# ECC_AGGR_ECC_AGGR_3F00F000h register map
Vendor: Texas Instruments
Peripheral module from a debugger description file (folder AM275x).
Registers are 32-bit, access not given, reset 0x0 unless marked. A register's access mark holds for its fields unless they carry their own. Offsets are as the file gives them; lines under a group give offsets from that group; [hi:lo] are bit positions; {n}, {i} and the like mark numbered series; 'fields as' and 'values as' point back to an identical list; <NAME> marks a mode.

## ecc_aggr
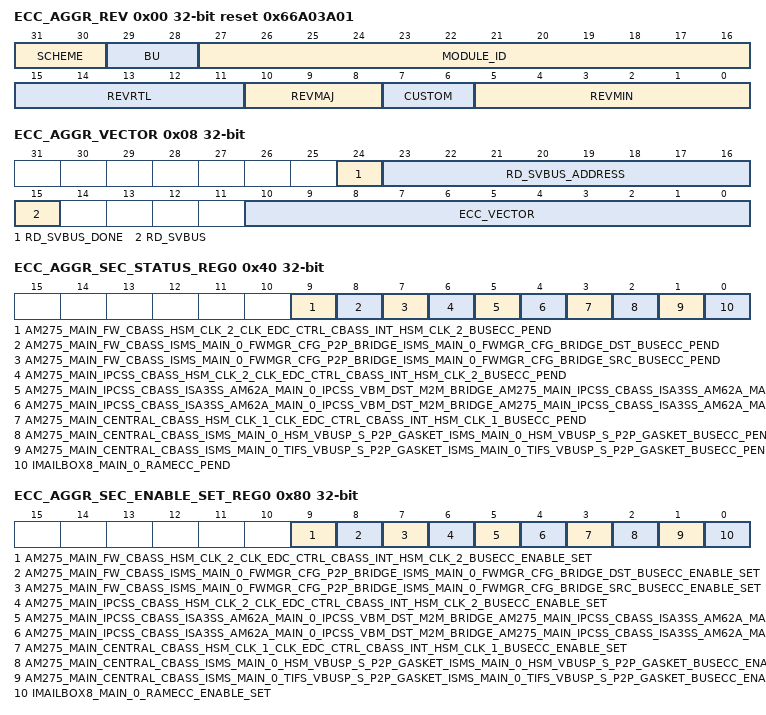
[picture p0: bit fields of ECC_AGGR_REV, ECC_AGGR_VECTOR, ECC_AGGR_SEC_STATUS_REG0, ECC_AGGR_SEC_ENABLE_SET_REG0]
0x00 ECC_AGGR_REV ro reset 0x66A03A01 — Revision parameters
  [31:30] SCHEME
  [29:28] BU — Business Unit
  [27:16] MODULE_ID
  [15:11] REVRTL — RTL version
  [10:8] REVMAJ — Major version
  [7:6] CUSTOM — Custom version
  [5:0] REVMIN — Minor version
0x08 ECC_AGGR_VECTOR — ECC Vector Register
  [24] RD_SVBUS_DONE — Status to indicate if read on serial VBUS is complete, write of any value will clear this bit. (access R/W1TC)
  [23:16] RD_SVBUS_ADDRESS rw — Read address
  [15] RD_SVBUS — Write 1 to trigger a read on the serial VBUS (access R/W1TS)
  [10:0] ECC_VECTOR rw — Value written to select the corresponding ECC RAM for control or status
0x0C ECC_AGGR_STAT ro reset 0xA — Misc Status
  [10:0] NUM_RAMS — Indicates the number of RAMS serviced by the ECC aggregator
0x10 ECC_AGGR_RESERVED_SVBUS_j rw — Reference other documents that contain the ECC RAM wrapper and EDC controller serial vbus register sets.
  [31:0] DATA — Serial VBUS register data
0x3C ECC_AGGR_SEC_EOI_REG — EOI Register
  [0] EOI_WR — EOI Register (access R/W1TS)
0x40 ECC_AGGR_SEC_STATUS_REG0 — Interrupt Status Register 0
  [9] AM275_MAIN_FW_CBASS_HSM_CLK_2_CLK_EDC_CTRL_CBASS_INT_HSM_CLK_2_BUSECC_PEND — Interrupt Pending Status for am275_main_fw_cbass_HSM_CLK_2_clk_edc_ctrl_cbass_int_HSM_CLK_2_busecc_pend (access R/W1TS)
  [8] AM275_MAIN_FW_CBASS_ISMS_MAIN_0_FWMGR_CFG_P2P_BRIDGE_ISMS_MAIN_0_FWMGR_CFG_BRIDGE_DST_BUSECC_PEND — Interrupt Pending Status for am275_main_fw_cbass_Isms_main_0_fwmgr_cfg_p2p_bridge_Isms_main_0_fwmgr_cfg_bridge_dst_busecc_pend (access R/W1TS)
  [7] AM275_MAIN_FW_CBASS_ISMS_MAIN_0_FWMGR_CFG_P2P_BRIDGE_ISMS_MAIN_0_FWMGR_CFG_BRIDGE_SRC_BUSECC_PEND — Interrupt Pending Status for am275_main_fw_cbass_Isms_main_0_fwmgr_cfg_p2p_bridge_Isms_main_0_fwmgr_cfg_bridge_src_busecc_pend (access R/W1TS)
  [6] AM275_MAIN_IPCSS_CBASS_HSM_CLK_2_CLK_EDC_CTRL_CBASS_INT_HSM_CLK_2_BUSECC_PEND — Interrupt Pending Status for am275_main_IPCSS_cbass_HSM_CLK_2_clk_edc_ctrl_cbass_int_HSM_CLK_2_busecc_pend (access R/W1TS)
  [5] AM275_MAIN_IPCSS_CBASS_ISA3SS_AM62A_MAIN_0_IPCSS_VBM_DST_M2M_BRIDGE_AM275_MAIN_IPCSS_CBASS_ISA3SS_AM62A_MAIN_0_IPCSS_VBM_DST_M2M_BRIDGE_DST_EDC_CTRL_BUSECC_PEND — Interrupt Pending Status for am275_main_IPCSS_cbass_Isa3ss_am62a_main_0_ipcss_vbm_dst_m2m_bridge_am275_main_IPCSS_cbass_Isa3ss_am62a_main_0_ipcss_vbm_dst_m2m_bridge_dst_edc_ctrl_busecc_pend (access R/W1TS)
  [4] AM275_MAIN_IPCSS_CBASS_ISA3SS_AM62A_MAIN_0_IPCSS_VBM_DST_M2M_BRIDGE_AM275_MAIN_IPCSS_CBASS_ISA3SS_AM62A_MAIN_0_IPCSS_VBM_DST_M2M_BRIDGE_SRC_EDC_CTRL_BUSECC_PEND — Interrupt Pending Status for am275_main_IPCSS_cbass_Isa3ss_am62a_main_0_ipcss_vbm_dst_m2m_bridge_am275_main_IPCSS_cbass_Isa3ss_am62a_main_0_ipcss_vbm_dst_m2m_bridge_src_edc_ctrl_busecc_pend (access R/W1TS)
  [3] AM275_MAIN_CENTRAL_CBASS_HSM_CLK_1_CLK_EDC_CTRL_CBASS_INT_HSM_CLK_1_BUSECC_PEND — Interrupt Pending Status for am275_main_central_cbass_HSM_CLK_1_clk_edc_ctrl_cbass_int_HSM_CLK_1_busecc_pend (access R/W1TS)
  [2] AM275_MAIN_CENTRAL_CBASS_ISMS_MAIN_0_HSM_VBUSP_S_P2P_GASKET_ISMS_MAIN_0_HSM_VBUSP_S_P2P_GASKET_BUSECC_PEND — Interrupt Pending Status for am275_main_central_cbass_Isms_main_0_hsm_vbusp_s_p2p_gasket_Isms_main_0_hsm_vbusp_s_p2p_gasket_busecc_pend (access R/W1TS)
  [1] AM275_MAIN_CENTRAL_CBASS_ISMS_MAIN_0_TIFS_VBUSP_S_P2P_GASKET_ISMS_MAIN_0_TIFS_VBUSP_S_P2P_GASKET_BUSECC_PEND — Interrupt Pending Status for am275_main_central_cbass_Isms_main_0_tifs_vbusp_s_p2p_gasket_Isms_main_0_tifs_vbusp_s_p2p_gasket_busecc_pend (access R/W1TS)
  [0] IMAILBOX8_MAIN_0_RAMECC_PEND — Interrupt Pending Status for Imailbox8_main_0_ramecc_pend (access R/W1TS)
0x80 ECC_AGGR_SEC_ENABLE_SET_REG0 — Interrupt Enable Set Register 0
  [9] AM275_MAIN_FW_CBASS_HSM_CLK_2_CLK_EDC_CTRL_CBASS_INT_HSM_CLK_2_BUSECC_ENABLE_SET — Interrupt Enable Set Register for am275_main_fw_cbass_HSM_CLK_2_clk_edc_ctrl_cbass_int_HSM_CLK_2_busecc_pend (access R/W1TS)
  [8] AM275_MAIN_FW_CBASS_ISMS_MAIN_0_FWMGR_CFG_P2P_BRIDGE_ISMS_MAIN_0_FWMGR_CFG_BRIDGE_DST_BUSECC_ENABLE_SET — Interrupt Enable Set Register for am275_main_fw_cbass_Isms_main_0_fwmgr_cfg_p2p_bridge_Isms_main_0_fwmgr_cfg_bridge_dst_busecc_pend (access R/W1TS)
  [7] AM275_MAIN_FW_CBASS_ISMS_MAIN_0_FWMGR_CFG_P2P_BRIDGE_ISMS_MAIN_0_FWMGR_CFG_BRIDGE_SRC_BUSECC_ENABLE_SET — Interrupt Enable Set Register for am275_main_fw_cbass_Isms_main_0_fwmgr_cfg_p2p_bridge_Isms_main_0_fwmgr_cfg_bridge_src_busecc_pend (access R/W1TS)
  [6] AM275_MAIN_IPCSS_CBASS_HSM_CLK_2_CLK_EDC_CTRL_CBASS_INT_HSM_CLK_2_BUSECC_ENABLE_SET — Interrupt Enable Set Register for am275_main_IPCSS_cbass_HSM_CLK_2_clk_edc_ctrl_cbass_int_HSM_CLK_2_busecc_pend (access R/W1TS)
  [5] AM275_MAIN_IPCSS_CBASS_ISA3SS_AM62A_MAIN_0_IPCSS_VBM_DST_M2M_BRIDGE_AM275_MAIN_IPCSS_CBASS_ISA3SS_AM62A_MAIN_0_IPCSS_VBM_DST_M2M_BRIDGE_DST_EDC_CTRL_BUSECC_ENABLE_SET — Interrupt Enable Set Register for am275_main_IPCSS_cbass_Isa3ss_am62a_main_0_ipcss_vbm_dst_m2m_bridge_am275_main_IPCSS_cbass_Isa3ss_am62a_main_0_ipcss_vbm_dst_m2m_bridge_dst_edc_ctrl_busecc_pend (access R/W1TS)
  [4] AM275_MAIN_IPCSS_CBASS_ISA3SS_AM62A_MAIN_0_IPCSS_VBM_DST_M2M_BRIDGE_AM275_MAIN_IPCSS_CBASS_ISA3SS_AM62A_MAIN_0_IPCSS_VBM_DST_M2M_BRIDGE_SRC_EDC_CTRL_BUSECC_ENABLE_SET — Interrupt Enable Set Register for am275_main_IPCSS_cbass_Isa3ss_am62a_main_0_ipcss_vbm_dst_m2m_bridge_am275_main_IPCSS_cbass_Isa3ss_am62a_main_0_ipcss_vbm_dst_m2m_bridge_src_edc_ctrl_busecc_pend (access R/W1TS)
  [3] AM275_MAIN_CENTRAL_CBASS_HSM_CLK_1_CLK_EDC_CTRL_CBASS_INT_HSM_CLK_1_BUSECC_ENABLE_SET — Interrupt Enable Set Register for am275_main_central_cbass_HSM_CLK_1_clk_edc_ctrl_cbass_int_HSM_CLK_1_busecc_pend (access R/W1TS)
  [2] AM275_MAIN_CENTRAL_CBASS_ISMS_MAIN_0_HSM_VBUSP_S_P2P_GASKET_ISMS_MAIN_0_HSM_VBUSP_S_P2P_GASKET_BUSECC_ENABLE_SET — Interrupt Enable Set Register for am275_main_central_cbass_Isms_main_0_hsm_vbusp_s_p2p_gasket_Isms_main_0_hsm_vbusp_s_p2p_gasket_busecc_pend (access R/W1TS)
  [1] AM275_MAIN_CENTRAL_CBASS_ISMS_MAIN_0_TIFS_VBUSP_S_P2P_GASKET_ISMS_MAIN_0_TIFS_VBUSP_S_P2P_GASKET_BUSECC_ENABLE_SET — Interrupt Enable Set Register for am275_main_central_cbass_Isms_main_0_tifs_vbusp_s_p2p_gasket_Isms_main_0_tifs_vbusp_s_p2p_gasket_busecc_pend (access R/W1TS)
  [0] IMAILBOX8_MAIN_0_RAMECC_ENABLE_SET — Interrupt Enable Set Register for Imailbox8_main_0_ramecc_pend (access R/W1TS)
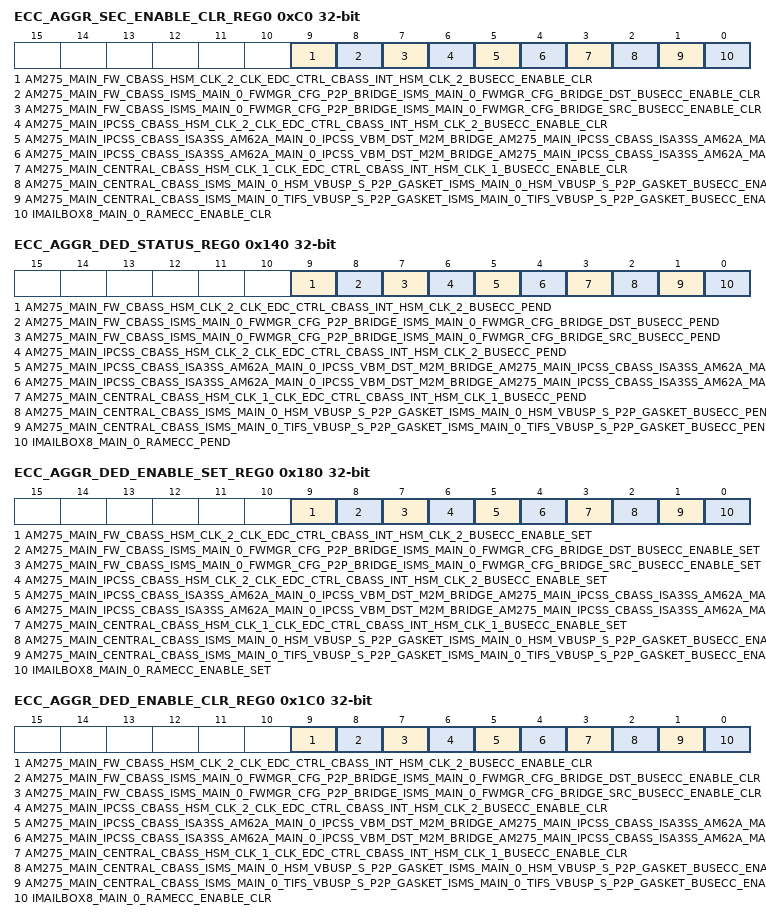
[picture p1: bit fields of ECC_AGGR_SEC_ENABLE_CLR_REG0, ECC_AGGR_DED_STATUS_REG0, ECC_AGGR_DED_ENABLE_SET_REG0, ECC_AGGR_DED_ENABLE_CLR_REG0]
0xC0 ECC_AGGR_SEC_ENABLE_CLR_REG0 — Interrupt Enable Clear Register 0
  [9] AM275_MAIN_FW_CBASS_HSM_CLK_2_CLK_EDC_CTRL_CBASS_INT_HSM_CLK_2_BUSECC_ENABLE_CLR — Interrupt Enable Clear Register for am275_main_fw_cbass_HSM_CLK_2_clk_edc_ctrl_cbass_int_HSM_CLK_2_busecc_pend (access R/W1TC)
  [8] AM275_MAIN_FW_CBASS_ISMS_MAIN_0_FWMGR_CFG_P2P_BRIDGE_ISMS_MAIN_0_FWMGR_CFG_BRIDGE_DST_BUSECC_ENABLE_CLR — Interrupt Enable Clear Register for am275_main_fw_cbass_Isms_main_0_fwmgr_cfg_p2p_bridge_Isms_main_0_fwmgr_cfg_bridge_dst_busecc_pend (access R/W1TC)
  [7] AM275_MAIN_FW_CBASS_ISMS_MAIN_0_FWMGR_CFG_P2P_BRIDGE_ISMS_MAIN_0_FWMGR_CFG_BRIDGE_SRC_BUSECC_ENABLE_CLR — Interrupt Enable Clear Register for am275_main_fw_cbass_Isms_main_0_fwmgr_cfg_p2p_bridge_Isms_main_0_fwmgr_cfg_bridge_src_busecc_pend (access R/W1TC)
  [6] AM275_MAIN_IPCSS_CBASS_HSM_CLK_2_CLK_EDC_CTRL_CBASS_INT_HSM_CLK_2_BUSECC_ENABLE_CLR — Interrupt Enable Clear Register for am275_main_IPCSS_cbass_HSM_CLK_2_clk_edc_ctrl_cbass_int_HSM_CLK_2_busecc_pend (access R/W1TC)
  [5] AM275_MAIN_IPCSS_CBASS_ISA3SS_AM62A_MAIN_0_IPCSS_VBM_DST_M2M_BRIDGE_AM275_MAIN_IPCSS_CBASS_ISA3SS_AM62A_MAIN_0_IPCSS_VBM_DST_M2M_BRIDGE_DST_EDC_CTRL_BUSECC_ENABLE_CLR — Interrupt Enable Clear Register for am275_main_IPCSS_cbass_Isa3ss_am62a_main_0_ipcss_vbm_dst_m2m_bridge_am275_main_IPCSS_cbass_Isa3ss_am62a_main_0_ipcss_vbm_dst_m2m_bridge_dst_edc_ctrl_busecc_pend (access R/W1TC)
  [4] AM275_MAIN_IPCSS_CBASS_ISA3SS_AM62A_MAIN_0_IPCSS_VBM_DST_M2M_BRIDGE_AM275_MAIN_IPCSS_CBASS_ISA3SS_AM62A_MAIN_0_IPCSS_VBM_DST_M2M_BRIDGE_SRC_EDC_CTRL_BUSECC_ENABLE_CLR — Interrupt Enable Clear Register for am275_main_IPCSS_cbass_Isa3ss_am62a_main_0_ipcss_vbm_dst_m2m_bridge_am275_main_IPCSS_cbass_Isa3ss_am62a_main_0_ipcss_vbm_dst_m2m_bridge_src_edc_ctrl_busecc_pend (access R/W1TC)
  [3] AM275_MAIN_CENTRAL_CBASS_HSM_CLK_1_CLK_EDC_CTRL_CBASS_INT_HSM_CLK_1_BUSECC_ENABLE_CLR — Interrupt Enable Clear Register for am275_main_central_cbass_HSM_CLK_1_clk_edc_ctrl_cbass_int_HSM_CLK_1_busecc_pend (access R/W1TC)
  [2] AM275_MAIN_CENTRAL_CBASS_ISMS_MAIN_0_HSM_VBUSP_S_P2P_GASKET_ISMS_MAIN_0_HSM_VBUSP_S_P2P_GASKET_BUSECC_ENABLE_CLR — Interrupt Enable Clear Register for am275_main_central_cbass_Isms_main_0_hsm_vbusp_s_p2p_gasket_Isms_main_0_hsm_vbusp_s_p2p_gasket_busecc_pend (access R/W1TC)
  [1] AM275_MAIN_CENTRAL_CBASS_ISMS_MAIN_0_TIFS_VBUSP_S_P2P_GASKET_ISMS_MAIN_0_TIFS_VBUSP_S_P2P_GASKET_BUSECC_ENABLE_CLR — Interrupt Enable Clear Register for am275_main_central_cbass_Isms_main_0_tifs_vbusp_s_p2p_gasket_Isms_main_0_tifs_vbusp_s_p2p_gasket_busecc_pend (access R/W1TC)
  [0] IMAILBOX8_MAIN_0_RAMECC_ENABLE_CLR — Interrupt Enable Clear Register for Imailbox8_main_0_ramecc_pend (access R/W1TC)
0x13C ECC_AGGR_DED_EOI_REG — EOI Register
  [0] EOI_WR — EOI Register (access R/W1TS)
0x140 ECC_AGGR_DED_STATUS_REG0 — Interrupt Status Register 0
  fields as ECC_AGGR_SEC_STATUS_REG0
0x180 ECC_AGGR_DED_ENABLE_SET_REG0 — Interrupt Enable Set Register 0
  fields as ECC_AGGR_SEC_ENABLE_SET_REG0
0x1C0 ECC_AGGR_DED_ENABLE_CLR_REG0 — Interrupt Enable Clear Register 0
  fields as ECC_AGGR_SEC_ENABLE_CLR_REG0
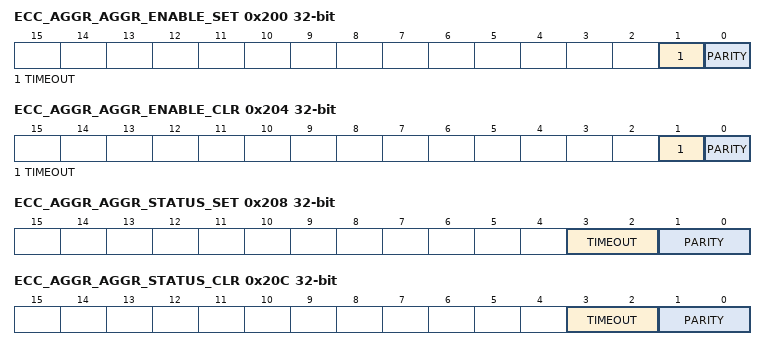
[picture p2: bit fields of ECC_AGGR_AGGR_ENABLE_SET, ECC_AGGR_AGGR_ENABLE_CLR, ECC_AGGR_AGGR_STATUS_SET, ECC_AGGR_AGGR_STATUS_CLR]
0x200 ECC_AGGR_AGGR_ENABLE_SET — AGGR interrupt enable set Register
  [1] TIMEOUT — interrupt enable set for svbus timeout errors (access R/W1TS)
  [0] PARITY — interrupt enable set for parity errors (access R/W1TS)
0x204 ECC_AGGR_AGGR_ENABLE_CLR — AGGR interrupt enable clear Register
  [1] TIMEOUT — interrupt enable clear for svbus timeout errors (access R/W1TC)
  [0] PARITY — interrupt enable clear for parity errors (access R/W1TC)
0x208 ECC_AGGR_AGGR_STATUS_SET — AGGR interrupt status set Register
  [3:2] TIMEOUT — interrupt status set for svbus timeout errors (access R/WI)
  [1:0] PARITY — interrupt status set for parity errors (access R/WI)
0x20C ECC_AGGR_AGGR_STATUS_CLR — AGGR interrupt status clear Register
  [3:2] TIMEOUT — interrupt status clear for svbus timeout errors (access R/WD)
  [1:0] PARITY — interrupt status clear for parity errors (access R/WD)
